# STM32H7S register map
File version: 1.0
CPU: CM7 r0p1, little endian, MPU, FPU, 4 interrupt priority bits
Registers are 32-bit, read-write, reset 0x0 unless marked. A register's access mark holds for its fields unless they carry their own. Offsets are from the block's base; [hi:lo] are bit positions; {n}, {i} and the like mark numbered series; 'fields as' and 'values as' point back to an identical list.

## GPIOA — General-purpose I/Os
Base 0x58020000
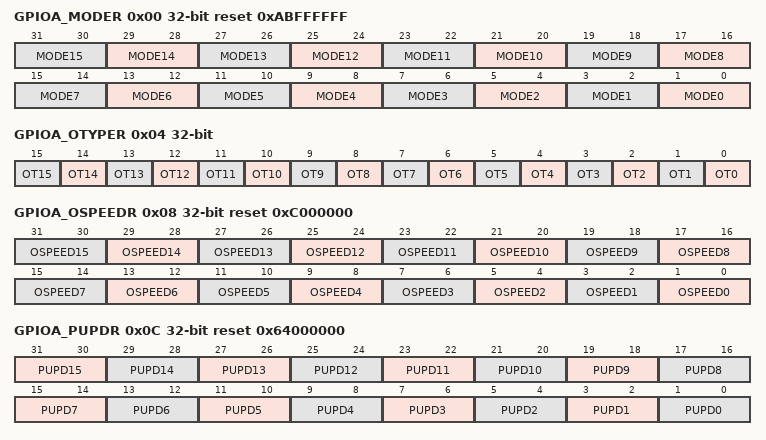
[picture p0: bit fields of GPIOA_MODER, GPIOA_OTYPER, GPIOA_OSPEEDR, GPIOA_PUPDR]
0x00 GPIOA_MODER reset 0xABFFFFFF — GPIO port mode register
  [all] fields
    0=Input mode; 1=General purpose output mode; 2=Alternate function mode; 3=Analog mode (reset state)
  [2n+1:2n] MODE{n} (n=0..15) — Port x configuration I/O pin y These bits are written by software to configure the I/O mode. Note: The bitfield is reserved and must be kept to reset value when the corresponding I/O is not available on the selected package.
0x04 GPIOA_OTYPER — GPIO port output type register
  [all] fields
    0=Output push-pull (reset state); 1=Output open-drain
  [n] OT{n} (n=0..15) — Port x configuration I/O pin y These bits are written by software to configure the I/O output type. Note: The bit is reserved and must be kept to reset value when the corresponding I/O is not available on the selected package.
0x08 GPIOA_OSPEEDR reset 0xC000000 — GPIO port output speed register
  [all] fields
    0=Low speed; 1=Medium speed; 2=High speed; 3=Very-high speed
  [2n+1:2n] OSPEED{n} (n=0..15) — Port x configuration I/O pin y These bits are written by software to configure the I/O output speed. Note: Refer to the device datasheet for the frequency specifications and the power supply and load conditions for each speed. Note: The bitfield is reserved and must be kept to reset value when the corresponding I/O is not available on the selected package.
0x0C GPIOA_PUPDR reset 0x64000000 — GPIO port pull-up/pull-down register
  [2n+1:2n] PUPD{n} (n=9..15) — Port x configuration I/O pin y These bits are written by software to configure the I/O pull-up or pull-down Note: The bitfield is reserved and must be kept to reset value when the corresponding I/O is not available on the selected package.
    0=No pull-up, pull-down; 1=Pull-up; 2=Pull-down; 3=FIELD Reserved
  [2n+1:2n] PUPD{n} (n=0..8) — Port x configuration I/O pin y These bits are written by software to configure the I/O pull-up or pull-down Note: The bitfield is reserved and must be kept to reset value when the corresponding I/O is not available on the selected package.
    0=No pull-up, pull-down; 1=Pull-up; 2=Pull-down
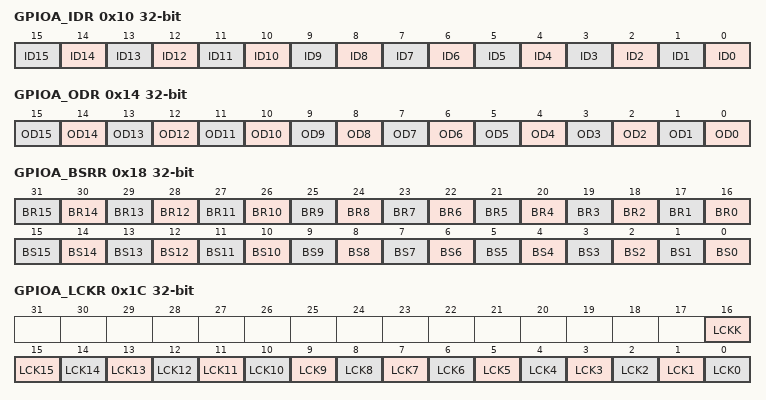
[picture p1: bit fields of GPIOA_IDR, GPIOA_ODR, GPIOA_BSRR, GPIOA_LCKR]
0x10 GPIOA_IDR ro (reset mask 0xFFFF0000) — GPIO port input data register
  [n] ID{n} (n=0..15) — Port x input data I/O pin y These bits are read-only. They contain the input value of the corresponding I/O port. Note: The bit is reserved and must be kept to reset value when the corresponding I/O is not available on the selected package.
0x14 GPIOA_ODR — GPIO port output data register
  [n] OD{n} (n=0..15) — Port output data I/O pin y These bits can be read and written by software. Note: For atomic bit set/reset, the OD bits can be individually set and/or reset by writing to the GPIOx_BSRR or GPIOx_BRR registers (x = A to G) (x = M to P). Note: The bit is reserved and must be kept to reset value when the corresponding I/O is not available on the selected package.
0x18 GPIOA_BSRR wo — GPIO port bit set/reset register
  [n+16] BR{n} (n=0..15) — Port x reset I/O pin y These bits are write-only. A read to these bits returns the value 0x0000. Note: If both BSy and BRy are set, BSy has priority. Note: The bit is reserved and must be kept to reset value when the corresponding I/O is not available on the selected package.
    0=No action on the corresponding ODy bit; 1=Resets the corresponding ODy bit
  [n] BS{n} (n=0..15) — Port x set I/O pin y These bits are write-only. A read to these bits returns the value 0x0000. Note: The bit is reserved and must be kept to reset value when the corresponding I/O is not available on the selected package.
    0=No action on the corresponding ODy bit; 1=Sets the corresponding ODy bit
0x1C GPIOA_LCKR — GPIO port configuration lock register
  [16] LCKK — Lock key This bit can be read any time. It can only be modified using the lock key write sequence. - LOCK key write sequence: WR LCKR[16] = 1 + LCKR[15:0] WR LCKR[16] = 0 + LCKR[15:0] WR LCKR[16] = 1 + LCKR[15:0] - LOCK key read RD LCKR[16] = 1 (this read operation is optional but it confirms that the lock is active) Note: During the LOCK key write sequence, the value of LCK[15:0] must not change. Note: Any error in the lock sequence aborts the LOCK. Note: After the first LOCK sequence on any bit of the port, any read access on the LCKK bit returns 1 until the next MCU reset or peripheral reset.
    0=Port configuration lock key not active; 1=Port configuration lock key active. The GPIOx_LCKR register is locked until the next MCU reset or peripheral reset.
  [n] LCK{n} (n=0..15) — Port x lock I/O pin y These bits are read/write but can only be written when the LCKK bit is 0 Note: The bit is reserved and must be kept to reset value when the corresponding I/O is not available on the selected package.
    0=Port configuration not locked; 1=Port configuration locked
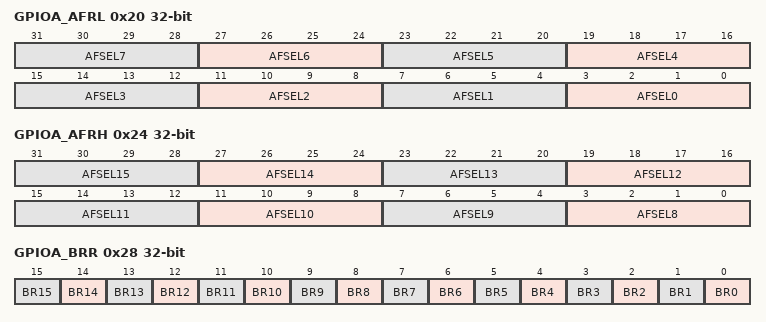
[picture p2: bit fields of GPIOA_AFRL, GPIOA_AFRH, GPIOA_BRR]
0x20 GPIOA_AFRL — GPIO alternate function low register
  [all] fields
    {v}=AF{v} (v=0..15)
  [4n+3:4n] AFSEL{n} (n=0..7) — Alternate function selection for port x I/O pin y These bits are written by software to configure alternate function I/Os. Note: The bitfield is reserved and must be kept to reset value when the corresponding I/O is not available on the selected package.
0x24 GPIOA_AFRH — GPIO alternate function high register
  [all] fields
    {v}=AF{v} (v=0..15)
  [4n-29:4n-32] AFSEL{n} (n=8..15) — Alternate function selection for port x I/O pin y These bits are written by software to configure alternate function I/Os. Note: The bitfield is reserved and must be kept to reset value when the corresponding I/O is not available on the selected package.
0x28 GPIOA_BRR wo — GPIO port bit reset register
  [all] fields
    0=No action on the corresponding ODy bit; 1=Reset the corresponding ODy bit
  [n] BR{n} (n=0..15) — Port x reset IO pin y These bits are write-only. A read to these bits returns the value 0x0000. Note: The bit is reserved and must be kept to reset value when the corresponding I/O is not available on the selected package.

## GPIOB — General-purpose I/Os
Base 0x58020400
Registers as GPIOA (with GPIOA read as GPIOB); these are added or differ:
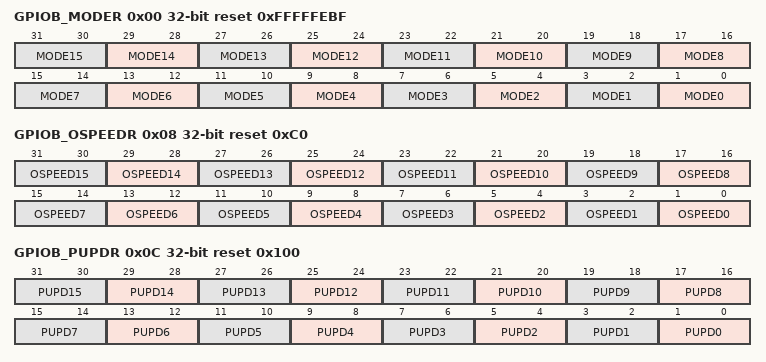
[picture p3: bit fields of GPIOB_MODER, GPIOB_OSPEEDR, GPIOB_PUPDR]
0x00 GPIOB_MODER reset 0xFFFFFEBF — GPIO port mode register
  fields as GPIOA.GPIOA_MODER
0x08 GPIOB_OSPEEDR reset 0xC0 — GPIO port output speed register
  fields as GPIOA.GPIOA_OSPEEDR
0x0C GPIOB_PUPDR reset 0x100 — GPIO port pull-up/pull-down register
  [all] fields
    0=No pull-up, pull-down; 1=Pull-up; 2=Pull-down; 3=FIELD Reserved
  [2n+1:2n] PUPD{n} (n=0..15) — Port x configuration I/O pin y These bits are written by software to configure the I/O pull-up or pull-down Note: The bitfield is reserved and must be kept to reset value when the corresponding I/O is not available on the selected package.

## GPIOC — General-purpose I/Os
Base 0x58020800
Registers as GPIOA (with GPIOA read as GPIOC); these are added or differ:
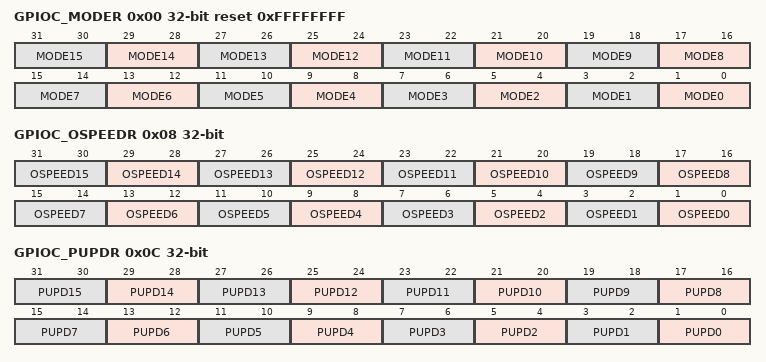
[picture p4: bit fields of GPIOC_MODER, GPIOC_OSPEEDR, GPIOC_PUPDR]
0x00 GPIOC_MODER reset 0xFFFFFFFF — GPIO port mode register
  fields as GPIOA.GPIOA_MODER
0x08 GPIOC_OSPEEDR — GPIO port output speed register
  fields as GPIOA.GPIOA_OSPEEDR
0x0C GPIOC_PUPDR — GPIO port pull-up/pull-down register
  fields as GPIOB.GPIOB_PUPDR

## GPIOD — General-purpose I/Os
Base 0x58020C00
Registers as GPIOC (with GPIOC read as GPIOD).

## GPIOE — General-purpose I/Os
Base 0x58021000
Registers as GPIOC (with GPIOC read as GPIOE).

## GPIOF — General-purpose I/Os
Base 0x58021400
Registers as GPIOC (with GPIOC read as GPIOF).

## GPIOG — General-purpose I/Os
Base 0x58021800
Registers as GPIOC (with GPIOC read as GPIOG).

## GPIOH — General-purpose I/Os
Base 0x58021C00
Registers as GPIOC (with GPIOC read as GPIOH).

## GPIOM — General-purpose I/Os
Base 0x58023000
Registers as GPIOC (with GPIOC read as GPIOM).

## GPION — General-purpose I/Os
Base 0x58023400
Registers as GPIOC (with GPIOC read as GPION).

## GPIOO — General-purpose I/Os
Base 0x58023800
Registers as GPIOC (with GPIOC read as GPIOO).

## GPIOP — GPIOP address block description
Base 0x58023C00
Registers as GPIOC (with GPIOC read as GPIOP).

## Notices in the file
Copyright (c) 2024 STMicroelectronics.
SPDX-License-Identifier: Apache-2.0
Licensed under the Apache License, Version 2.0 (the "License");
you may not use this file except in compliance with the License.
You may obtain a copy of the License at
http://www.apache.org/licenses/LICENSE-2.0
Unless required by applicable law or agreed to in writing, software
distributed under the License is distributed on an "AS IS" BASIS,
WITHOUT WARRANTIES OR CONDITIONS OF ANY KIND, either express or implied.
See the License for the specific language governing permissions and
limitations under the License.
